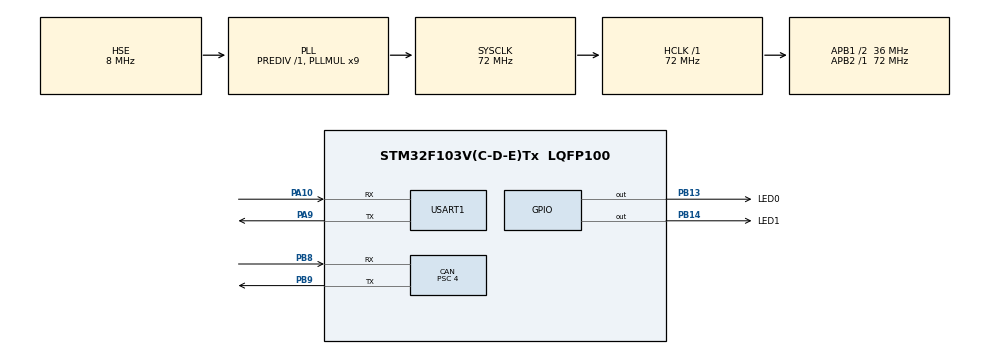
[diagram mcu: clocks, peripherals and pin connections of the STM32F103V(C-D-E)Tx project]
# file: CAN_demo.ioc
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CAN.BS1=CAN_BS1_15TQ
CAN.BS2=CAN_BS2_2TQ
CAN.CalculateTimeBit=2000
CAN.CalculateTimeQuantum=111.11111111111111
CAN.Mode=CAN_MODE_NORMAL
CAN.NART=ENABLE
CAN.Prescaler=4
CAN.SJW=CAN_SJW_1TQ
CAN.TXFP=ENABLE
Mcu.Family=STM32F1
Mcu.Name=STM32F103V(C-D-E)Tx
Mcu.Package=LQFP100
NVIC.CAN1_SCE_IRQn=true\:2\:0\:true\:false\:true\:true\:true
NVIC.PriorityGroup=NVIC_PRIORITYGROUP_4
NVIC.TIM7_IRQn=true\:0\:0\:false\:false\:true\:false\:true
NVIC.TimeBase=TIM7_IRQn
NVIC.TimeBaseIP=TIM7
NVIC.USB_LP_CAN1_RX0_IRQn=true\:2\:0\:true\:false\:true\:true\:true
OSC_IN.Mode=HSE-External-Oscillator
OSC_IN.Signal=RCC_OSC_IN
OSC_OUT.Mode=HSE-External-Oscillator
OSC_OUT.Signal=RCC_OSC_OUT
PA10.Mode=Asynchronous
PA10.Signal=USART1_RX
PA13.Mode=Trace_Asynchronous_SW
PA13.Signal=SYS_JTMS-SWDIO
PA14.Mode=Trace_Asynchronous_SW
PA14.Signal=SYS_JTCK-SWCLK
PA9.Mode=Asynchronous
PA9.Signal=USART1_TX
PB13.GPIO_Label=LED0
PB13.GPIO_PuPd=GPIO_PULLDOWN
PB13.PinState=GPIO_PIN_SET
PB13.Signal=GPIO_Output
PB14.GPIO_Label=LED1
PB14.GPIO_PuPd=GPIO_PULLDOWN
PB14.PinState=GPIO_PIN_SET
PB14.Signal=GPIO_Output
PB3.Mode=Trace_Asynchronous_SW
PB3.Signal=SYS_JTDO-TRACESWO
PB8.Mode=Master
PB8.Signal=CAN_RX
PB9.Mode=Master
PB9.Signal=CAN_TX
PC14-OSC32_IN.Mode=LSE-External-Oscillator
PC14-OSC32_IN.Signal=RCC_OSC32_IN
PC15-OSC32_OUT.Mode=LSE-External-Oscillator
PC15-OSC32_OUT.Signal=RCC_OSC32_OUT
ProjectManager.HeapSize=0x200
ProjectManager.StackSize=0x400
ProjectManager.TargetToolchain=STM32CubeIDE
RCC.ADCPresc=RCC_ADCPCLK2_DIV6
RCC.AHBFreq_Value=72000000
RCC.APB1CLKDivider=RCC_HCLK_DIV2
RCC.APB1Freq_Value=36000000
RCC.APB1TimFreq_Value=72000000
RCC.APB2Freq_Value=72000000
RCC.APB2TimFreq_Value=72000000
RCC.EnbaleCSS=true
RCC.HCLKFreq_Value=72000000
RCC.PLLMUL=RCC_PLL_MUL9
RCC.PLLSourceVirtual=RCC_PLLSOURCE_HSE
RCC.SYSCLKFreq_VALUE=72000000
RCC.SYSCLKSource=RCC_SYSCLKSOURCE_PLLCLK
RCC.USBFreq_Value=72000000
USART1.VirtualMode=VM_ASYNC
VP_SYS_VS_tim7.Mode=TIM7
board=custom

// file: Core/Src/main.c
/* USER CODE BEGIN Header */
/**
  ******************************************************************************
  * @file           : main.c
  * @brief          : Main program body
  ******************************************************************************
  * @attention
  *
  * <h2><center>&copy; Copyright (c) 2020 STMicroelectronics.
  * All rights reserved.</center></h2>
  *
  * This software component is licensed by ST under BSD 3-Clause license,
  * the "License"; You may not use this file except in compliance with the
  * License. You may obtain a copy of the License at:
  *                        opensource.org/licenses/BSD-3-Clause
  *
  ******************************************************************************
  */
/* USER CODE END Header */
#include "main.h"
#include "can.h"
#include "usart.h"
#include "gpio.h"

/* USER CODE BEGIN Includes */
#include "bsp_led.h"
#include "bsp_debug.h"
/* USER CODE END Includes */

void SystemClock_Config(void);

int main(void)
{

  /* MCU Configuration--------------------------------------------------------*/

  /* Reset of all peripherals, Initializes the Flash interface and the Systick. */
  HAL_Init();

  /* Configure the system clock */
  SystemClock_Config();

  /* Initialize all configured peripherals */
  MX_GPIO_Init();
  MX_CAN_Init();
  MX_USART1_UART_Init();
  /* USER CODE BEGIN 2 */
  CAN_Config();

  uint32_t CAN_time_temp = 0;
  uint32_t systick_temp = 0;
  uint32_t led_time_temp = 0;
  /* USER CODE END 2 */

  /* Infinite loop */
  while (1)
  {

    /* USER CODE BEGIN 3 */

     /*CAN Rx Message interval time should less than 1s*/
	//  CAN_time_temp = CAN_RxMessage_time;
	//  led_time_temp = led_time;
	//  systick_temp = HAL_GetTick();
	//  if(systick_temp > CAN_time_temp)
	//  {
	// 	 if ((systick_temp - CAN_time_temp) > CAN_RxMessage_time_interval_Max)
	// 	      {
	// 	        LED0_ON;
	// 	      }
	//  }

	//  if(systick_temp > led_time_temp)
	//  {
	// 	 if ((systick_temp-led_time_temp) > led_delay_time)
	//      {
	// 		 LED1_OFF;
	//       }
	//  }

   /* Set the data to be transmitted */
   CAN_TxData[0] = 3;
   CAN_TxData[1] = 2;
   CAN_TxData[2] = 0;
   CAN_TxHeader.StdId = 0x320;
   CAN_TxHeader.DLC = 3;

   /* Start the Transmission process */
   if (HAL_CAN_AddTxMessage(&hcan, &CAN_TxHeader, CAN_TxData, &CAN_TxMailbox) != HAL_OK)
   {
     /* Transmission request Error */
     Error_Handler();
   }
   HAL_Delay(5);
  }
  /* USER CODE END 3 */
}

void SystemClock_Config(void)
{
  RCC_OscInitTypeDef RCC_OscInitStruct = {0};
  RCC_ClkInitTypeDef RCC_ClkInitStruct = {0};

  /** Initializes the RCC Oscillators according to the specified parameters
  * in the RCC_OscInitTypeDef structure.
  */
  RCC_OscInitStruct.OscillatorType = RCC_OSCILLATORTYPE_HSE;
  RCC_OscInitStruct.HSEState = RCC_HSE_ON;
  RCC_OscInitStruct.HSEPredivValue = RCC_HSE_PREDIV_DIV1;
  RCC_OscInitStruct.HSIState = RCC_HSI_ON;
  RCC_OscInitStruct.PLL.PLLState = RCC_PLL_ON;
  RCC_OscInitStruct.PLL.PLLSource = RCC_PLLSOURCE_HSE;
  RCC_OscInitStruct.PLL.PLLMUL = RCC_PLL_MUL9;
  if (HAL_RCC_OscConfig(&RCC_OscInitStruct) != HAL_OK)
  {
    Error_Handler();
  }
  /** Initializes the CPU, AHB and APB buses clocks
  */
  RCC_ClkInitStruct.ClockType = RCC_CLOCKTYPE_HCLK|RCC_CLOCKTYPE_SYSCLK
                              |RCC_CLOCKTYPE_PCLK1|RCC_CLOCKTYPE_PCLK2;
  RCC_ClkInitStruct.SYSCLKSource = RCC_SYSCLKSOURCE_PLLCLK;
  RCC_ClkInitStruct.AHBCLKDivider = RCC_SYSCLK_DIV1;
  RCC_ClkInitStruct.APB1CLKDivider = RCC_HCLK_DIV2;
  RCC_ClkInitStruct.APB2CLKDivider = RCC_HCLK_DIV1;

  if (HAL_RCC_ClockConfig(&RCC_ClkInitStruct, FLASH_LATENCY_2) != HAL_OK)
  {
    Error_Handler();
  }
  /** Enables the Clock Security System
  */
  HAL_RCC_EnableCSS();
}

void HAL_TIM_PeriodElapsedCallback(TIM_HandleTypeDef *htim)
{
  if (htim->Instance == TIM7) {
    HAL_IncTick();
  }
}

void Error_Handler(void)
{
}

/************************ (C) COPYRIGHT STMicroelectronics *****END OF FILE****/
